AUTOSAR XML (schema 00049)
package /vwg/applications/@EXECUTABLE_NAME@/design
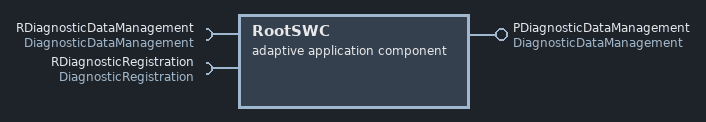
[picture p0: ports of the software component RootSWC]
  adaptive application sw component type RootSWC
    provide port PDiagnosticDataManagement: provided-interface=DiagnosticDataManagement
    require port RDiagnosticDataManagement: required-interface=DiagnosticDataManagement
    require port RDiagnosticRegistration: required-interface=DiagnosticRegistration
  executable @EXECUTABLE_NAME@: category=APPLICATION_LEVEL, version=1.0.0
    root sw component prototype @EXECUTABLE_NAME@RootSWC: application-type=RootSWC
  process design @EXECUTABLE_NAME@ProcessDesign: executable=@EXECUTABLE_NAME@
